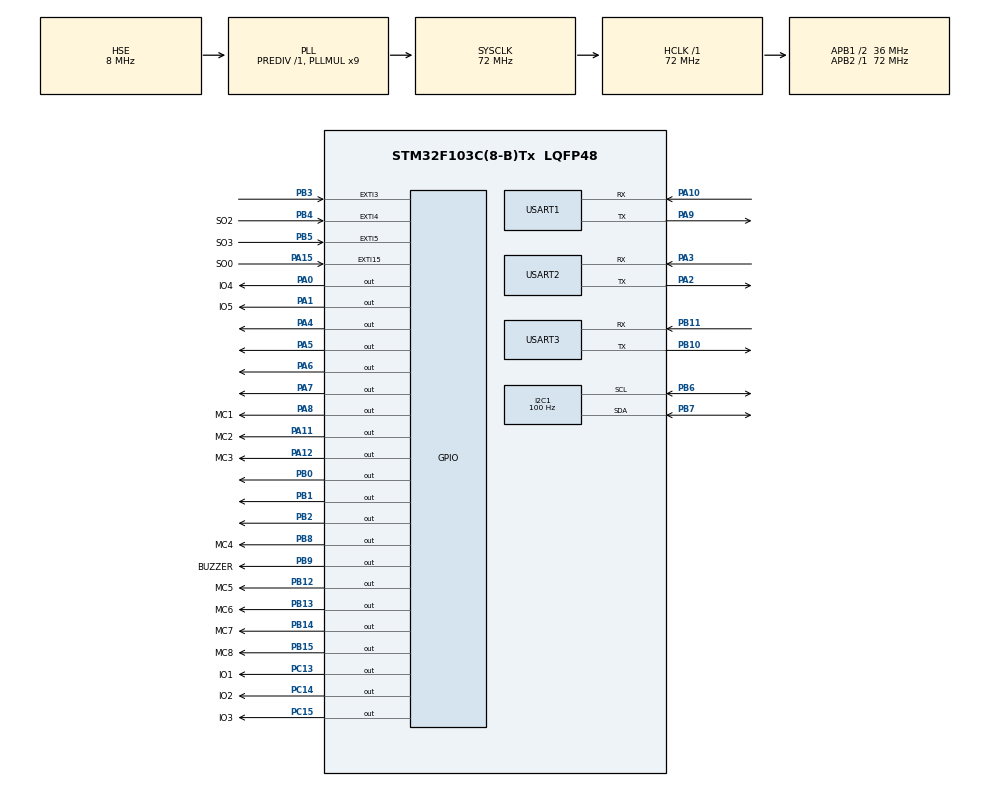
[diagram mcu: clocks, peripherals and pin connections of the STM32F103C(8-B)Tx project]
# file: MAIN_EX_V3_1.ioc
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FREERTOS.Tasks01=defaultTask,0,128,StartDefaultTask,Default,NULL,Dynamic,NULL,NULL;myTask02,-3,128,StartTask02,Default,NULL,Dynamic,NULL,NULL;myTask03,-3,128,StartTask03,Default,NULL,Dynamic,NULL,NULL;myTask04,-3,128,StartTask04,Default,NULL,Dynamic,NULL,NULL;myTask05,-3,128,StartTask05,Default,NULL,Dynamic,NULL,NULL;myTask06,-3,128,StartTask06,Default,NULL,Dynamic,NULL,NULL
FREERTOS.configTOTAL_HEAP_SIZE=15360
I2C1.ClockSpeed=100
Mcu.Family=STM32F1
Mcu.Name=STM32F103C(8-B)Tx
Mcu.Package=LQFP48
NVIC.EXTI15_10_IRQn=true\:6\:0\:true\:false\:true\:true\:true\:true\:true
NVIC.EXTI3_IRQn=true\:6\:0\:true\:false\:true\:true\:true\:true\:true
NVIC.EXTI4_IRQn=true\:7\:0\:true\:false\:true\:true\:true\:true\:true
NVIC.EXTI9_5_IRQn=true\:7\:0\:true\:false\:true\:true\:true\:true\:true
NVIC.PriorityGroup=NVIC_PRIORITYGROUP_4
NVIC.USART1_IRQn=true\:5\:0\:false\:false\:true\:true\:true\:true\:true
NVIC.USART3_IRQn=true\:5\:0\:false\:false\:true\:true\:true\:true\:true
PA0-WKUP.GPIO_Label=IO4
PA0-WKUP.GPIO_Speed=GPIO_SPEED_FREQ_HIGH
PA0-WKUP.Signal=GPIO_Output
PA1.GPIO_Label=IO5
PA1.GPIO_Speed=GPIO_SPEED_FREQ_HIGH
PA1.Signal=GPIO_Output
PA10.Mode=Asynchronous
PA10.Signal=USART1_RX
PA11.GPIO_Label=MC2
PA11.GPIO_Speed=GPIO_SPEED_FREQ_HIGH
PA11.Signal=GPIO_Output
PA12.GPIO_Label=MC3
PA12.GPIO_Speed=GPIO_SPEED_FREQ_HIGH
PA12.Signal=GPIO_Output
PA13.Mode=Serial_Wire
PA13.Signal=SYS_JTMS-SWDIO
PA14.Mode=Serial_Wire
PA14.Signal=SYS_JTCK-SWCLK
PA15.GPIO_Label=SO0
PA15.GPIO_ModeDefaultEXTI=GPIO_MODE_IT_FALLING
PA15.Signal=GPXTI15
PA2.Mode=Asynchronous
PA2.Signal=USART2_TX
PA3.Mode=Asynchronous
PA3.Signal=USART2_RX
PA4.Signal=GPIO_Output
PA5.Signal=GPIO_Output
PA6.Signal=GPIO_Output
PA7.Signal=GPIO_Output
PA8.GPIO_Label=MC1
PA8.GPIO_Speed=GPIO_SPEED_FREQ_HIGH
PA8.Signal=GPIO_Output
PA9.Mode=Asynchronous
PA9.Signal=USART1_TX
PB0.Signal=GPIO_Output
PB1.Signal=GPIO_Output
PB10.Mode=Asynchronous
PB10.Signal=USART3_TX
PB11.Mode=Asynchronous
PB11.Signal=USART3_RX
PB12.GPIO_Label=MC5
PB12.Signal=GPIO_Output
PB13.GPIO_Label=MC6
PB13.Signal=GPIO_Output
PB14.GPIO_Label=MC7
PB14.Signal=GPIO_Output
PB15.GPIO_Label=MC8
PB15.Signal=GPIO_Output
PB2.Signal=GPIO_Output
PB3.GPIO_ModeDefaultEXTI=GPIO_MODE_IT_RISING_FALLING
PB3.Signal=GPXTI3
PB4.GPIO_Label=SO2
PB4.GPIO_ModeDefaultEXTI=GPIO_MODE_IT_FALLING
PB4.Signal=GPXTI4
PB5.GPIO_Label=SO3
PB5.GPIO_ModeDefaultEXTI=GPIO_MODE_IT_FALLING
PB5.Signal=GPXTI5
PB6.Mode=I2C
PB6.Signal=I2C1_SCL
PB7.Mode=I2C
PB7.Signal=I2C1_SDA
PB8.GPIO_Label=MC4
PB8.Signal=GPIO_Output
PB8.Stacked=true
PB9.GPIO_Label=BUZZER
PB9.GPIO_Speed=GPIO_SPEED_FREQ_HIGH
PB9.Signal=GPIO_Output
PC13-TAMPER-RTC.GPIO_Label=IO1
PC13-TAMPER-RTC.GPIO_Speed=GPIO_SPEED_FREQ_HIGH
PC13-TAMPER-RTC.Signal=GPIO_Output
PC14-OSC32_IN.GPIO_Label=IO2
PC14-OSC32_IN.GPIO_Speed=GPIO_SPEED_FREQ_HIGH
PC14-OSC32_IN.Signal=GPIO_Output
PC15-OSC32_OUT.GPIO_Label=IO3
PC15-OSC32_OUT.GPIO_Speed=GPIO_SPEED_FREQ_HIGH
PC15-OSC32_OUT.Signal=GPIO_Output
PD0-OSC_IN.Mode=HSE-External-Oscillator
PD0-OSC_IN.Signal=RCC_OSC_IN
PD1-OSC_OUT.Mode=HSE-External-Oscillator
PD1-OSC_OUT.Signal=RCC_OSC_OUT
ProjectManager.HeapSize=0x200
ProjectManager.StackSize=0x400
ProjectManager.TargetToolchain=MDK-ARM V5.32
RCC.ADCPresc=RCC_ADCPCLK2_DIV6
RCC.AHBFreq_Value=72000000
RCC.APB1CLKDivider=RCC_HCLK_DIV2
RCC.APB1Freq_Value=36000000
RCC.APB1TimFreq_Value=72000000
RCC.APB2Freq_Value=72000000
RCC.APB2TimFreq_Value=72000000
RCC.HCLKFreq_Value=72000000
RCC.PLLMUL=RCC_PLL_MUL9
RCC.PLLSourceVirtual=RCC_PLLSOURCE_HSE
RCC.SYSCLKFreq_VALUE=72000000
RCC.SYSCLKSource=RCC_SYSCLKSOURCE_PLLCLK
RCC.USBFreq_Value=72000000
USART1.VirtualMode=VM_ASYNC
USART2.VirtualMode=VM_ASYNC
USART3.VirtualMode=VM_ASYNC
VP_FREERTOS_VS_CMSIS_V1.Mode=CMSIS_V1
board=custom

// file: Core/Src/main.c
/* USER CODE BEGIN Header */
/**
  ******************************************************************************
  * @file           : main.c
  * @brief          : Main program body
  ******************************************************************************
  * @attention
  *
  * Copyright (c) 2023 STMicroelectronics.
  * All rights reserved.
  *
  * This software is licensed under terms that can be found in the LICENSE file
  * in the root directory of this software component.
  * If no LICENSE file comes with this software, it is provided AS-IS.
  *
  ******************************************************************************
  */
/* USER CODE END Header */
#include "main.h"
#include "cmsis_os.h"

I2C_HandleTypeDef hi2c1;

UART_HandleTypeDef huart1;
UART_HandleTypeDef huart2;
UART_HandleTypeDef huart3;

osThreadId defaultTaskHandle;
osThreadId myTask02Handle;
osThreadId myTask03Handle;
osThreadId myTask04Handle;
osThreadId myTask05Handle;
osThreadId myTask06Handle;

void SystemClock_Config(void);
static void MX_GPIO_Init(void);
static void MX_I2C1_Init(void);
static void MX_USART1_UART_Init(void);
static void MX_USART2_UART_Init(void);
static void MX_USART3_UART_Init(void);
void StartDefaultTask(void const * argument);
void StartTask02(void const * argument);
void StartTask03(void const * argument);
void StartTask04(void const * argument);
void StartTask05(void const * argument);
void StartTask06(void const * argument);

int main(void)
{

  /* MCU Configuration--------------------------------------------------------*/

  /* Reset of all peripherals, Initializes the Flash interface and the Systick. */
  HAL_Init();

  /* Configure the system clock */
  SystemClock_Config();

  /* Initialize all configured peripherals */
  MX_GPIO_Init();
  MX_I2C1_Init();
  MX_USART1_UART_Init();
  MX_USART2_UART_Init();
  MX_USART3_UART_Init();
  /* USER CODE BEGIN 2 */
  FEE_RTOS_Innit();
	 control_xilanh(1,0);
	 control_xilanh(2,0);
	 control_xilanh(3,0);
	 control_xilanh(4,0);
	 control_xilanh(5,0);
	 control_xilanh(6,0);
	 control_xilanh(7,0);
	 control_xilanh(8,0);

  /* USER CODE END 2 */

  /* Create the thread(s) */
  /* definition and creation of defaultTask */
  osThreadDef(defaultTask, StartDefaultTask, osPriorityNormal, 0, 128);
  defaultTaskHandle = osThreadCreate(osThread(defaultTask), NULL);

  /* definition and creation of myTask02 */
  osThreadDef(myTask02, StartTask02, osPriorityIdle, 0, 128);
  myTask02Handle = osThreadCreate(osThread(myTask02), NULL);

  /* definition and creation of myTask03 */
  osThreadDef(myTask03, StartTask03, osPriorityIdle, 0, 128);
  myTask03Handle = osThreadCreate(osThread(myTask03), NULL);

  /* definition and creation of myTask04 */
  osThreadDef(myTask04, StartTask04, osPriorityIdle, 0, 128);
  myTask04Handle = osThreadCreate(osThread(myTask04), NULL);

  /* definition and creation of myTask05 */
  osThreadDef(myTask05, StartTask05, osPriorityIdle, 0, 128);
  myTask05Handle = osThreadCreate(osThread(myTask05), NULL);

  /* definition and creation of myTask06 */
  osThreadDef(myTask06, StartTask06, osPriorityIdle, 0, 128);
  myTask06Handle = osThreadCreate(osThread(myTask06), NULL);

  /* Start scheduler */
  osKernelStart();

  /* We should never get here as control is now taken by the scheduler */
  /* Infinite loop */
  while (1)
  {

  }
}

void SystemClock_Config(void)
{
  RCC_OscInitTypeDef RCC_OscInitStruct = {0};
  RCC_ClkInitTypeDef RCC_ClkInitStruct = {0};

  /** Initializes the RCC Oscillators according to the specified parameters
  * in the RCC_OscInitTypeDef structure.
  */
  RCC_OscInitStruct.OscillatorType = RCC_OSCILLATORTYPE_HSE;
  RCC_OscInitStruct.HSEState = RCC_HSE_ON;
  RCC_OscInitStruct.HSEPredivValue = RCC_HSE_PREDIV_DIV1;
  RCC_OscInitStruct.HSIState = RCC_HSI_ON;
  RCC_OscInitStruct.PLL.PLLState = RCC_PLL_ON;
  RCC_OscInitStruct.PLL.PLLSource = RCC_PLLSOURCE_HSE;
  RCC_OscInitStruct.PLL.PLLMUL = RCC_PLL_MUL9;
  if (HAL_RCC_OscConfig(&RCC_OscInitStruct) != HAL_OK)
  {
    Error_Handler();
  }

  /** Initializes the CPU, AHB and APB buses clocks
  */
  RCC_ClkInitStruct.ClockType = RCC_CLOCKTYPE_HCLK|RCC_CLOCKTYPE_SYSCLK
                              |RCC_CLOCKTYPE_PCLK1|RCC_CLOCKTYPE_PCLK2;
  RCC_ClkInitStruct.SYSCLKSource = RCC_SYSCLKSOURCE_PLLCLK;
  RCC_ClkInitStruct.AHBCLKDivider = RCC_SYSCLK_DIV1;
  RCC_ClkInitStruct.APB1CLKDivider = RCC_HCLK_DIV2;
  RCC_ClkInitStruct.APB2CLKDivider = RCC_HCLK_DIV1;

  if (HAL_RCC_ClockConfig(&RCC_ClkInitStruct, FLASH_LATENCY_2) != HAL_OK)
  {
    Error_Handler();
  }
}

static void MX_I2C1_Init(void)
{

  hi2c1.Instance = I2C1;
  hi2c1.Init.ClockSpeed = 100;
  hi2c1.Init.DutyCycle = I2C_DUTYCYCLE_2;
  hi2c1.Init.OwnAddress1 = 0;
  hi2c1.Init.AddressingMode = I2C_ADDRESSINGMODE_7BIT;
  hi2c1.Init.DualAddressMode = I2C_DUALADDRESS_DISABLE;
  hi2c1.Init.OwnAddress2 = 0;
  hi2c1.Init.GeneralCallMode = I2C_GENERALCALL_DISABLE;
  hi2c1.Init.NoStretchMode = I2C_NOSTRETCH_DISABLE;
  if (HAL_I2C_Init(&hi2c1) != HAL_OK)
  {
    Error_Handler();
  }

}

static void MX_USART1_UART_Init(void)
{

  huart1.Instance = USART1;
  huart1.Init.BaudRate = 115200;
  huart1.Init.WordLength = UART_WORDLENGTH_8B;
  huart1.Init.StopBits = UART_STOPBITS_1;
  huart1.Init.Parity = UART_PARITY_NONE;
  huart1.Init.Mode = UART_MODE_TX_RX;
  huart1.Init.HwFlowCtl = UART_HWCONTROL_NONE;
  huart1.Init.OverSampling = UART_OVERSAMPLING_16;
  if (HAL_UART_Init(&huart1) != HAL_OK)
  {
    Error_Handler();
  }

}

static void MX_USART2_UART_Init(void)
{

  huart2.Instance = USART2;
  huart2.Init.BaudRate = 115200;
  huart2.Init.WordLength = UART_WORDLENGTH_8B;
  huart2.Init.StopBits = UART_STOPBITS_1;
  huart2.Init.Parity = UART_PARITY_NONE;
  huart2.Init.Mode = UART_MODE_TX_RX;
  huart2.Init.HwFlowCtl = UART_HWCONTROL_NONE;
  huart2.Init.OverSampling = UART_OVERSAMPLING_16;
  if (HAL_UART_Init(&huart2) != HAL_OK)
  {
    Error_Handler();
  }

}

static void MX_USART3_UART_Init(void)
{

  huart3.Instance = USART3;
  huart3.Init.BaudRate = 115200;
  huart3.Init.WordLength = UART_WORDLENGTH_8B;
  huart3.Init.StopBits = UART_STOPBITS_1;
  huart3.Init.Parity = UART_PARITY_NONE;
  huart3.Init.Mode = UART_MODE_TX_RX;
  huart3.Init.HwFlowCtl = UART_HWCONTROL_NONE;
  huart3.Init.OverSampling = UART_OVERSAMPLING_16;
  if (HAL_UART_Init(&huart3) != HAL_OK)
  {
    Error_Handler();
  }

}

static void MX_GPIO_Init(void)
{
  GPIO_InitTypeDef GPIO_InitStruct = {0};

  /* GPIO Ports Clock Enable */
  __HAL_RCC_GPIOC_CLK_ENABLE();
  __HAL_RCC_GPIOD_CLK_ENABLE();
  __HAL_RCC_GPIOA_CLK_ENABLE();
  __HAL_RCC_GPIOB_CLK_ENABLE();

  /*Configure GPIO pin Output Level */
  HAL_GPIO_WritePin(GPIOC, IO1_Pin|IO2_Pin|IO3_Pin, GPIO_PIN_RESET);

  /*Configure GPIO pin Output Level */
  HAL_GPIO_WritePin(GPIOA, IO4_Pin|IO5_Pin|GPIO_PIN_4|GPIO_PIN_5
                          |GPIO_PIN_6|GPIO_PIN_7|MC1_Pin|MC2_Pin
                          |MC3_Pin, GPIO_PIN_RESET);

  /*Configure GPIO pin Output Level */
  HAL_GPIO_WritePin(GPIOB, GPIO_PIN_0|GPIO_PIN_1|GPIO_PIN_2|MC5_Pin
                          |MC6_Pin|MC7_Pin|MC8_Pin|MC4_Pin
                          |BUZZER_Pin, GPIO_PIN_RESET);

  /*Configure GPIO pins : IO1_Pin IO2_Pin IO3_Pin */
  GPIO_InitStruct.Pin = IO1_Pin|IO2_Pin|IO3_Pin;
  GPIO_InitStruct.Mode = GPIO_MODE_OUTPUT_PP;
  GPIO_InitStruct.Pull = GPIO_NOPULL;
  GPIO_InitStruct.Speed = GPIO_SPEED_FREQ_HIGH;
  HAL_GPIO_Init(GPIOC, &GPIO_InitStruct);

  /*Configure GPIO pins : IO4_Pin IO5_Pin MC1_Pin MC2_Pin
                           MC3_Pin */
  GPIO_InitStruct.Pin = IO4_Pin|IO5_Pin|MC1_Pin|MC2_Pin
                          |MC3_Pin;
  GPIO_InitStruct.Mode = GPIO_MODE_OUTPUT_PP;
  GPIO_InitStruct.Pull = GPIO_NOPULL;
  GPIO_InitStruct.Speed = GPIO_SPEED_FREQ_HIGH;
  HAL_GPIO_Init(GPIOA, &GPIO_InitStruct);

  /*Configure GPIO pins : PA4 PA5 PA6 PA7 */
  GPIO_InitStruct.Pin = GPIO_PIN_4|GPIO_PIN_5|GPIO_PIN_6|GPIO_PIN_7;
  GPIO_InitStruct.Mode = GPIO_MODE_OUTPUT_PP;
  GPIO_InitStruct.Pull = GPIO_NOPULL;
  GPIO_InitStruct.Speed = GPIO_SPEED_FREQ_LOW;
  HAL_GPIO_Init(GPIOA, &GPIO_InitStruct);

  /*Configure GPIO pins : PB0 PB1 PB2 MC5_Pin
                           MC6_Pin MC7_Pin MC8_Pin MC4_Pin */
  GPIO_InitStruct.Pin = GPIO_PIN_0|GPIO_PIN_1|GPIO_PIN_2|MC5_Pin
                          |MC6_Pin|MC7_Pin|MC8_Pin|MC4_Pin;
  GPIO_InitStruct.Mode = GPIO_MODE_OUTPUT_PP;
  GPIO_InitStruct.Pull = GPIO_NOPULL;
  GPIO_InitStruct.Speed = GPIO_SPEED_FREQ_LOW;
  HAL_GPIO_Init(GPIOB, &GPIO_InitStruct);

  /*Configure GPIO pin : SO0_Pin */
  GPIO_InitStruct.Pin = SO0_Pin;
  GPIO_InitStruct.Mode = GPIO_MODE_IT_FALLING;
  GPIO_InitStruct.Pull = GPIO_NOPULL;
  HAL_GPIO_Init(SO0_GPIO_Port, &GPIO_InitStruct);

  /*Configure GPIO pin : PB3 */
  GPIO_InitStruct.Pin = GPIO_PIN_3;
  GPIO_InitStruct.Mode = GPIO_MODE_IT_RISING_FALLING;
  GPIO_InitStruct.Pull = GPIO_NOPULL;
  HAL_GPIO_Init(GPIOB, &GPIO_InitStruct);

  /*Configure GPIO pins : SO2_Pin SO3_Pin */
  GPIO_InitStruct.Pin = SO2_Pin|SO3_Pin;
  GPIO_InitStruct.Mode = GPIO_MODE_IT_FALLING;
  GPIO_InitStruct.Pull = GPIO_NOPULL;
  HAL_GPIO_Init(GPIOB, &GPIO_InitStruct);

  /*Configure GPIO pin : BUZZER_Pin */
  GPIO_InitStruct.Pin = BUZZER_Pin;
  GPIO_InitStruct.Mode = GPIO_MODE_OUTPUT_PP;
  GPIO_InitStruct.Pull = GPIO_NOPULL;
  GPIO_InitStruct.Speed = GPIO_SPEED_FREQ_HIGH;
  HAL_GPIO_Init(BUZZER_GPIO_Port, &GPIO_InitStruct);

  /* EXTI interrupt init*/
  HAL_NVIC_SetPriority(EXTI3_IRQn, 6, 0);
  HAL_NVIC_EnableIRQ(EXTI3_IRQn);

  HAL_NVIC_SetPriority(EXTI4_IRQn, 7, 0);
  HAL_NVIC_EnableIRQ(EXTI4_IRQn);

  HAL_NVIC_SetPriority(EXTI9_5_IRQn, 7, 0);
  HAL_NVIC_EnableIRQ(EXTI9_5_IRQn);

  HAL_NVIC_SetPriority(EXTI15_10_IRQn, 6, 0);
  HAL_NVIC_EnableIRQ(EXTI15_10_IRQn);

}

void Error_Handler(void)
{
  __disable_irq();
  while (1)
  {
  }
}
